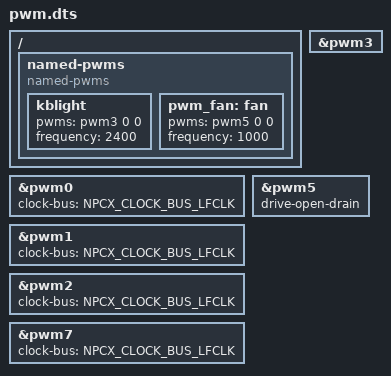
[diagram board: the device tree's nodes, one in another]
/* Copyright 2022 The Chromium OS Authors. All rights reserved.
 * Use of this source code is governed by a BSD-style license that can be
 * found in the LICENSE file.
 */

/ {
	named-pwms {
		compatible = "named-pwms";

		kblight: kblight {
			pwms = <&pwm3 0 0>;
			frequency = <2400>;
		};
		pwm_fan: fan {
			pwms = <&pwm5 0 0>;
			frequency = <1000>;
		};
	};
};

/* LED2 */
&pwm0 {
	status = "okay";
	clock-bus = "NPCX_CLOCK_BUS_LFCLK";
};

/* LED3 */
&pwm1 {
	status = "okay";
	clock-bus = "NPCX_CLOCK_BUS_LFCLK";
};

/* LED1 */
&pwm2 {
	status = "okay";
	clock-bus = "NPCX_CLOCK_BUS_LFCLK";
};

/* Keyboard backlight */
&pwm3 {
	status = "okay";
};

/* Fan control */
&pwm5 {
	status = "okay";
	drive-open-drain;
};

/* LED4 */
&pwm7 {
	status = "okay";
	clock-bus = "NPCX_CLOCK_BUS_LFCLK";
};
